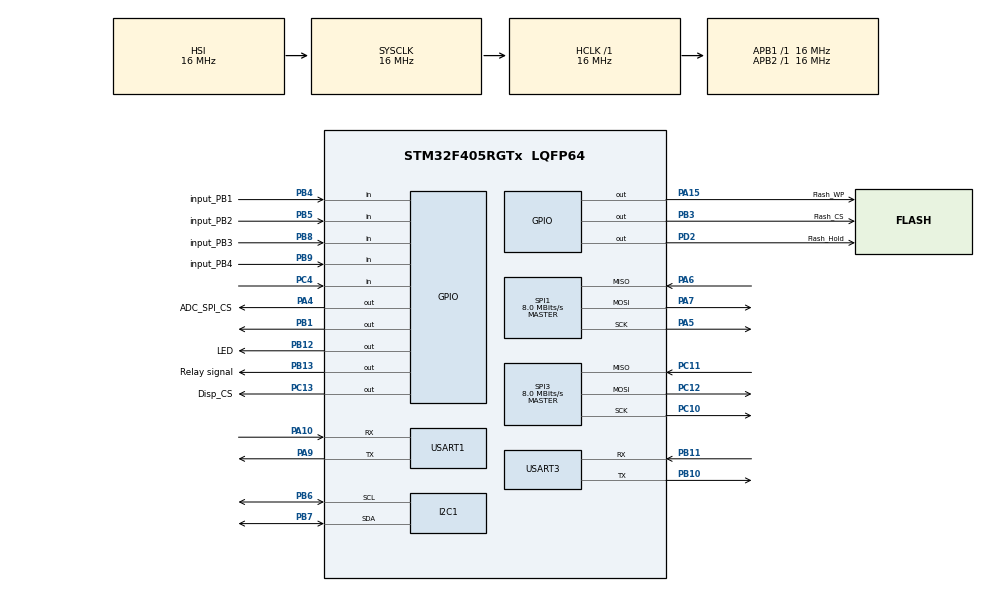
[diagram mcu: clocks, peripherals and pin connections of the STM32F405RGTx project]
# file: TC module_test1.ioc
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ADC1.Channel-0\#ChannelRegularConversion=ADC_CHANNEL_TEMPSENSOR
ADC1.NbrOfConversionFlag=1
ADC1.Rank-0\#ChannelRegularConversion=1
ADC1.SamplingTime-0\#ChannelRegularConversion=ADC_SAMPLETIME_3CYCLES
ADC1.master=1
Dma.Request0=SPI1_RX
Dma.Request1=SPI1_TX
Dma.SPI1_RX.0.Direction=DMA_PERIPH_TO_MEMORY
Dma.SPI1_RX.0.FIFOMode=DMA_FIFOMODE_DISABLE
Dma.SPI1_RX.0.Instance=DMA2_Stream0
Dma.SPI1_RX.0.MemDataAlignment=DMA_MDATAALIGN_BYTE
Dma.SPI1_RX.0.MemInc=DMA_MINC_ENABLE
Dma.SPI1_RX.0.Mode=DMA_CIRCULAR
Dma.SPI1_RX.0.PeriphDataAlignment=DMA_PDATAALIGN_BYTE
Dma.SPI1_RX.0.PeriphInc=DMA_PINC_DISABLE
Dma.SPI1_RX.0.Priority=DMA_PRIORITY_LOW
Dma.SPI1_TX.1.Direction=DMA_MEMORY_TO_PERIPH
Dma.SPI1_TX.1.FIFOMode=DMA_FIFOMODE_DISABLE
Dma.SPI1_TX.1.Instance=DMA2_Stream3
Dma.SPI1_TX.1.MemDataAlignment=DMA_MDATAALIGN_BYTE
Dma.SPI1_TX.1.MemInc=DMA_MINC_ENABLE
Dma.SPI1_TX.1.Mode=DMA_NORMAL
Dma.SPI1_TX.1.PeriphDataAlignment=DMA_PDATAALIGN_BYTE
Dma.SPI1_TX.1.PeriphInc=DMA_PINC_DISABLE
Dma.SPI1_TX.1.Priority=DMA_PRIORITY_LOW
Mcu.Family=STM32F4
Mcu.Name=STM32F405RGTx
Mcu.Package=LQFP64
NVIC.DMA2_Stream0_IRQn=true\:0\:0\:false\:false\:true\:false\:true\:true
NVIC.DMA2_Stream3_IRQn=true\:0\:0\:false\:false\:true\:false\:true\:true
NVIC.PriorityGroup=NVIC_PRIORITYGROUP_4
NVIC.TIM7_IRQn=true\:15\:0\:false\:false\:true\:false\:true\:true
NVIC.TimeBase=TIM7_IRQn
NVIC.TimeBaseIP=TIM7
PA10.Mode=Asynchronous
PA10.Signal=USART1_RX
PA13.Mode=Serial_Wire
PA13.Signal=SYS_JTMS-SWDIO
PA14.Mode=Serial_Wire
PA14.Signal=SYS_JTCK-SWCLK
PA15.GPIO_Label=Flash_WP
PA15.Signal=GPIO_Output
PA4.GPIO_Label=ADC_SPI_CS
PA4.Signal=GPIO_Output
PA5.Mode=Full_Duplex_Master
PA5.Signal=SPI1_SCK
PA6.Mode=Full_Duplex_Master
PA6.Signal=SPI1_MISO
PA7.Mode=Full_Duplex_Master
PA7.Signal=SPI1_MOSI
PA9.Mode=Asynchronous
PA9.Signal=USART1_TX
PB1.Signal=GPIO_Output
PB10.Mode=Asynchronous
PB10.Signal=USART3_TX
PB11.Mode=Asynchronous
PB11.Signal=USART3_RX
PB12.GPIO_Label=LED
PB12.Signal=GPIO_Output
PB13.GPIO_Label=Relay signal
PB13.Signal=GPIO_Output
PB3.GPIO_Label=Flash_CS
PB3.Signal=GPIO_Output
PB4.GPIO_Label=input_PB1
PB4.Signal=GPIO_Input
PB5.GPIO_Label=input_PB2
PB5.Signal=GPIO_Input
PB6.Mode=I2C
PB6.Signal=I2C1_SCL
PB7.Mode=I2C
PB7.Signal=I2C1_SDA
PB8.GPIO_Label=input_PB3
PB8.Signal=GPIO_Input
PB9.GPIO_Label=input_PB4
PB9.Signal=GPIO_Input
PC10.Mode=Full_Duplex_Master
PC10.Signal=SPI3_SCK
PC11.Mode=Full_Duplex_Master
PC11.Signal=SPI3_MISO
PC12.Mode=Full_Duplex_Master
PC12.Signal=SPI3_MOSI
PC13-ANTI_TAMP.GPIO_Label=Disp_CS
PC13-ANTI_TAMP.Signal=GPIO_Output
PC14-OSC32_IN.Mode=LSE-External-Clock-Source
PC14-OSC32_IN.Signal=RCC_OSC32_IN
PC15-OSC32_OUT.Mode=LSE-External-Clock-Source
PC15-OSC32_OUT.Signal=RCC_OSC32_OUT
PC2.Signal=SPI2_MISO
PC3.Signal=SPI2_MOSI
PC4.Signal=GPIO_Input
PD2.GPIO_Label=Flash_Hold
PD2.Signal=GPIO_Output
PH0-OSC_IN.Mode=HSE-External-Clock-Source
PH0-OSC_IN.Signal=RCC_OSC_IN
PH1-OSC_OUT.Mode=HSE-External-Clock-Source
PH1-OSC_OUT.Signal=RCC_OSC_OUT
ProjectManager.HeapSize=0x200
ProjectManager.StackSize=0x400
ProjectManager.TargetToolchain=STM32CubeIDE
RCC.AHBFreq_Value=16000000
RCC.APB1Freq_Value=16000000
RCC.APB2Freq_Value=16000000
RCC.CortexFreq_Value=16000000
RCC.HSE_VALUE=25000000
RCC.HSI_VALUE=16000000
RCC.LSE_VALUE=32768
RCC.SYSCLKFreq_VALUE=16000000
RCC.VCOOutputFreq_Value=192000000
SPI1.CalculateBaudRate=8.0 MBits/s
SPI1.Direction=SPI_DIRECTION_2LINES
SPI1.Mode=SPI_MODE_MASTER
SPI1.VirtualType=VM_MASTER
SPI3.CalculateBaudRate=8.0 MBits/s
SPI3.Direction=SPI_DIRECTION_2LINES
SPI3.Mode=SPI_MODE_MASTER
SPI3.VirtualType=VM_MASTER
USART1.VirtualMode=VM_ASYNC
USART3.VirtualMode=VM_ASYNC
VP_ADC1_TempSens_Input.Mode=IN-TempSens
VP_RTC_VS_RTC_Activate.Mode=RTC_Enabled
VP_SYS_VS_tim7.Mode=TIM7
board=custom

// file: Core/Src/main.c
/* USER CODE BEGIN Header */
/**
  ******************************************************************************
  * @file           : main.c
  * @brief          : Main program body
  ******************************************************************************
  * @attention
  *
  * Copyright (c) 2026 STMicroelectronics.
  * All rights reserved.
  *
  * This software is licensed under terms that can be found in the LICENSE file
  * in the root directory of this software component.
  * If no LICENSE file comes with this software, it is provided AS-IS.
  *
  ******************************************************************************
  */
/* USER CODE END Header */
#include "main.h"
#include "adc.h"
#include "dma.h"
#include "i2c.h"
#include "rtc.h"
#include "spi.h"
#include "usart.h"
#include "gpio.h"

/* USER CODE BEGIN Includes */
#include "SPI_driver.h"
/* USER CODE END Includes */

void SystemClock_Config(void);

int main(void)
{

  /* MCU Configuration--------------------------------------------------------*/

  /* Reset of all peripherals, Initializes the Flash interface and the Systick. */
  HAL_Init();

  /* Configure the system clock */
  SystemClock_Config();

  /* Initialize all configured peripherals */
  MX_GPIO_Init();
  MX_DMA_Init();
  MX_I2C1_Init();
  MX_RTC_Init();
  MX_SPI1_Init();
  MX_SPI3_Init();
  MX_USART1_UART_Init();
  MX_USART3_UART_Init();
  MX_ADC1_Init();
  //SPI_Init();
  /* Infinite loop */
  while (1)
  {

  }
}

void SystemClock_Config(void)
{
  RCC_OscInitTypeDef RCC_OscInitStruct = {0};
  RCC_ClkInitTypeDef RCC_ClkInitStruct = {0};

  /** Configure the main internal regulator output voltage
  */
  __HAL_RCC_PWR_CLK_ENABLE();
  __HAL_PWR_VOLTAGESCALING_CONFIG(PWR_REGULATOR_VOLTAGE_SCALE1);

  /** Initializes the RCC Oscillators according to the specified parameters
  * in the RCC_OscInitTypeDef structure.
  */
  RCC_OscInitStruct.OscillatorType = RCC_OSCILLATORTYPE_HSI|RCC_OSCILLATORTYPE_LSI;
  RCC_OscInitStruct.HSIState = RCC_HSI_ON;
  RCC_OscInitStruct.HSICalibrationValue = RCC_HSICALIBRATION_DEFAULT;
  RCC_OscInitStruct.LSIState = RCC_LSI_ON;
  RCC_OscInitStruct.PLL.PLLState = RCC_PLL_NONE;
  if (HAL_RCC_OscConfig(&RCC_OscInitStruct) != HAL_OK)
  {
    Error_Handler();
  }

  /** Initializes the CPU, AHB and APB buses clocks
  */
  RCC_ClkInitStruct.ClockType = RCC_CLOCKTYPE_HCLK|RCC_CLOCKTYPE_SYSCLK
                              |RCC_CLOCKTYPE_PCLK1|RCC_CLOCKTYPE_PCLK2;
  RCC_ClkInitStruct.SYSCLKSource = RCC_SYSCLKSOURCE_HSI;
  RCC_ClkInitStruct.AHBCLKDivider = RCC_SYSCLK_DIV1;
  RCC_ClkInitStruct.APB1CLKDivider = RCC_HCLK_DIV1;
  RCC_ClkInitStruct.APB2CLKDivider = RCC_HCLK_DIV1;

  if (HAL_RCC_ClockConfig(&RCC_ClkInitStruct, FLASH_LATENCY_0) != HAL_OK)
  {
    Error_Handler();
  }
}

void HAL_TIM_PeriodElapsedCallback(TIM_HandleTypeDef *htim)
{
  if (htim->Instance == TIM7)
  {
    HAL_IncTick();
  }
}

void Error_Handler(void)
{
  __disable_irq();
  while (1)
  {
  }
}
